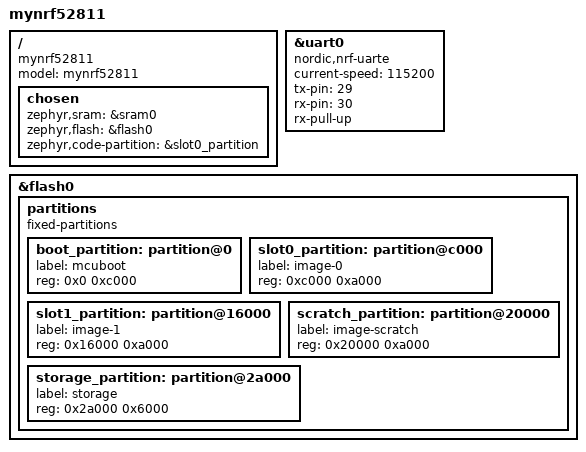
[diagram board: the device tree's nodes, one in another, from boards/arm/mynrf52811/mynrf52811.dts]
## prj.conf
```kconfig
# 配置文件

# 使能串口
CONFIG_SERIAL=y
CONFIG_NRFX_UARTE0=y
CONFIG_UART_ASYNC_API=y

# 使能以及配置蓝牙
CONFIG_BT=y
CONFIG_BT_DEVICE_NAME="ble_thomas"
CONFIG_BT_HCI_TX_STACK_SIZE=640
CONFIG_BT_PERIPHERAL=y
CONFIG_BT_PHY_UPDATE=n
CONFIG_BT_DATA_LEN_UPDATE=n
CONFIG_BT_BUF_EVT_RX_COUNT=2
CONFIG_BT_BUF_EVT_DISCARDABLE_COUNT=1
CONFIG_BT_ASSERT=n
CONFIG_BT_HCI_TX_STACK_SIZE_WITH_PROMPT=y
CONFIG_BT_MAX_PAIRED=1
CONFIG_BT_L2CAP_TX_BUF_COUNT=2
CONFIG_BT_GATT_SERVICE_CHANGED=n
CONFIG_BT_GAP_PERIPHERAL_PREF_PARAMS=n
CONFIG_BT_CTLR_PRIVACY=n
CONFIG_BT_MAX_CONN=1


# 内存优化，修改部分任务内存占用
CONFIG_DEBUG_THREAD_INFO=y
CONFIG_DEBUG_OPTIMIZATIONS=y
CONFIG_SYSTEM_WORKQUEUE_STACK_SIZE=1536
CONFIG_MAIN_STACK_SIZE=512
CONFIG_IDLE_STACK_SIZE=128
CONFIG_ISR_STACK_SIZE=1024
CONFIG_TIMESLICING=n

CONFIG_BT_EXT_ADV=y
CONFIG_BT_PER_ADV=y
CONFIG_BT_DF=y
CONFIG_BT_DF_CONNECTIONLESS_CTE_RX=y
CONFIG_BT_DF_CTE_RX_AOA=n
CONFIG_BT_OBSERVER=y
CONFIG_BT_PER_ADV_SYNC=y
```

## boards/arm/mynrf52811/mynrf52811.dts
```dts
// Copyright (c) 2022 Nordic Semiconductor ASA
// SPDX-License-Identifier: Apache-2.0

/dts-v1/;
#include <nordic/nrf52811_qfaa.dtsi>

/ {
	model = "mynrf52811";
	compatible = "mynrf52811";

	chosen {
		zephyr,sram = &sram0;
		zephyr,flash = &flash0;
		zephyr,code-partition = &slot0_partition;
	};
};

&uart0 {
	compatible = "nordic,nrf-uarte";
	status = "okay";
	current-speed = <115200>;
	tx-pin = <29>;
	rx-pin = <30>;
	rx-pull-up;
   //  rts-pin = <2>;
   //  cts-pin = <31>;
   //  cts-pull-up;
};


&flash0 {
	partitions {
		compatible = "fixed-partitions";
		#address-cells = <1>;
		#size-cells = <1>;

		boot_partition: partition@0 {
			label = "mcuboot";
			reg = <0x0 0xc000>;
		};
		slot0_partition: partition@c000 {
			label = "image-0";
			reg = <0xc000 0xa000>;
		};
		slot1_partition: partition@16000 {
			label = "image-1";
			reg = <0x16000 0xa000>;
		};
		scratch_partition: partition@20000 {
			label = "image-scratch";
			reg = <0x20000 0xa000>;
		};
		storage_partition: partition@2a000 {
			label = "storage";
			reg = <0x2a000 0x6000>;
		};
	};
};
```

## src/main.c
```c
/****
 * 
 * 
 * */
#include <zephyr.h>
#include "mybluetooth.h"
#include "myuart.h"
#include "uart_profile.h"


K_THREAD_DEFINE(ble_write_thread_id, BT_UART_STACKSIZE, ble_write_thread, NULL, NULL,
		NULL, BT_UART_PRIORITY, 0, 0);

void main(void)
{
	int err;
	
	NRFX_DELAY_US(1000000);
	uart_init();

	err = bt_enable(NULL);
	if (err){
		printk("ble init faild\r\n");
	}
	/* 发送初始化成功的消息 */
	k_sem_give(&ble_init_ok);
	printk("ble init success!\r\n");
	ble_had_been_inited = 1;

	/* 开始广播 */
	bt_advertising_start();
	while (1){
		printk("hello world\r\n");
		k_sleep(K_MSEC(2000));
	}
}
```

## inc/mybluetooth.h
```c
#ifndef __MYBLUETOOTH_H
#define __MYBLUETOOTH_H

#include <drivers/uart.h>
#include <bluetooth/bluetooth.h>
#include <bluetooth/hci.h>

#define DEVICE_NAME CONFIG_BT_DEVICE_NAME
#define DEVICE_NAME_LEN (sizeof(DEVICE_NAME) - 1)

extern uint8_t ble_had_been_inited;
extern struct bt_conn *current_conn;

void bt_scan_enable(void);
void bt_advertising_start(void);
void connected_cb(struct bt_conn *conn, uint8_t err);
void disconnected_cb(struct bt_conn *conn, uint8_t reason);
void scan_cb(const bt_addr_le_t *addr, int8_t rssi, uint8_t adv_type, struct net_buf_simple *buf);


#endif
```

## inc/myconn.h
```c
#ifndef __MYCONN_H
#define __MYCONN_H

#include <bluetooth/bluetooth.h>


void connected(struct bt_conn *conn, uint8_t err);
void disconnected(struct bt_conn *conn, uint8_t reason);

#endif
```

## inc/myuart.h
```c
#ifndef __MYUART_H
#define __MYUART_H

#include <drivers/uart.h>

#define UART_BUF_SIZE 40
#define UART_RX_TIMEOUT 50

/* 串口数据格式 */
struct uart_data_t {
	void *fifo_reserved;
	uint8_t  data[UART_BUF_SIZE];
	uint16_t len;
};

extern const struct device *uart;

int uart_init(void);
void ble_write_thread(void);

void uart_cb(const struct device *, struct uart_event *, void *);


#endif
```

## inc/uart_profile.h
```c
#ifndef __UART_PROFILE_H
#define __UART_PROFILE_H

#include <drivers/uart.h>
#include "bluetooth/uuid.h"
#include "bluetooth/gatt.h"


/* 串口透传服务UUID */
#define UART_TP_UUID_VAL BT_UUID_128_ENCODE(0x64f499cc,0x3411, 0x461d, 0x8055, 0x333d0bc7d33c)

/* 发送特征UUID */
#define UART_TX_UUID_VAL BT_UUID_128_ENCODE(0x64f499cd,0x3411, 0x461d, 0x8055, 0x333d0bc7d33c)

/* 接收特征UUID */
#define UART_RX_UUID_VAL BT_UUID_128_ENCODE(0x64f499ce,0x3411, 0x461d, 0x8055, 0x333d0bc7d33c)

#define BT_UUID_UART_TP        BT_UUID_DECLARE_128(UART_TP_UUID_VAL)
#define BT_UUID_UART_RX        BT_UUID_DECLARE_128(UART_TX_UUID_VAL)
#define BT_UUID_UART_TX        BT_UUID_DECLARE_128(UART_RX_UUID_VAL)


#define BT_UART_STACKSIZE 256
#define BT_UART_PRIORITY 7

extern struct k_sem ble_init_ok;

/* 串口透传状态 */
enum bt_uart_send_status {
	/* 发送通知使能 */
	BT_UART_SEND_STATUS_ENABLED,
	/* 发送通知停止使能 */
	BT_UART_SEND_STATUS_DISABLED,
};


void bt_uart_ccc_cfg_changed(const struct bt_gatt_attr *, uint16_t);
ssize_t ble_uart_receive_cb(struct bt_conn*, const struct bt_gatt_attr*, const void*, uint16_t, uint16_t, uint8_t);


#endif
```

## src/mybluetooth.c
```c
#include "mybluetooth.h"
#include "uart_profile.h"


/* 蓝牙初始化完成标志 */
uint8_t ble_had_been_inited = 0;

struct bt_conn *current_conn;

/* 连接相关回调函数注册 */
BT_CONN_CB_DEFINE(conn_callbacks) = {
	.connected    = connected_cb,
	.disconnected = disconnected_cb,
};


/* 广播发送的信息 */
static const struct bt_data ad[] = {
	BT_DATA_BYTES(BT_DATA_FLAGS, (BT_LE_AD_GENERAL | BT_LE_AD_NO_BREDR)),
	BT_DATA(BT_DATA_NAME_COMPLETE, DEVICE_NAME, DEVICE_NAME_LEN),
}; 

/* 对方扫描回应的信息 */
static const struct bt_data sd[] = {
	BT_DATA_BYTES(BT_DATA_UUID128_ALL, UART_TP_UUID_VAL),
};

/* 扫描参数 */
const struct bt_le_scan_param scan_param = {
		.type       = BT_HCI_LE_SCAN_PASSIVE,
		.options    = BT_LE_SCAN_OPT_NONE,
		.interval   = 0x00A0,
		.window     = 0x0050,
	};


/**
 * @brief 蓝牙开始广播 
 */
void bt_advertising_start(void){
	int err;
	/* Start advertising */
	err = bt_le_adv_start(BT_LE_ADV_CONN, ad, ARRAY_SIZE(ad),
			      sd, ARRAY_SIZE(sd));
    if (err) {
		printk("Advertising failed to start (err %d)\r\n", err);
		return;
	}
	printk("Advertising started!\r\n");
}


/**
 * @brief 初始化并开始扫描 
 */
void bt_scan_enable(void){
	int err;

	err = bt_le_scan_start(&scan_param, scan_cb);
	if (err) {
		printk("Starting scanning failed (err %d)\n", err);
		return;
	}
}

/**
 * @brief 扫描回调函数，每次扫描到东西都会进入到里面
 * 
 * @param addr 		：广播方地址
 * @param rssi 		：接收功率
 * @param adv_type 	：类型，被动扫描还是主动扫描（可以用来判断是广播数据还是扫描响应数据）
 * @param buf 		：接收的广播数据
 */
void scan_cb(const bt_addr_le_t *addr, int8_t rssi, uint8_t adv_type,
		    struct net_buf_simple *buf)
{
	static uint8_t name_buf[11] = {0};
	if (adv_type == BT_HCI_LE_SCAN_PASSIVE){
		if (buf->len > 10){
			if ((uint8_t)buf->data[3] == 11){
				memcpy(name_buf, &(buf->data[5]), 10);
				printk("name is: %s \r\n", name_buf);
				printk("rssi is: %d \r\n", rssi);
			}
		}
	}
}


/**
 * @brief 连接成功回调函数
 * 
 * @param conn 	:连接句柄
 * @param err 	:连接错误
 */
void connected_cb(struct bt_conn *conn, uint8_t err)
{

	if (err) {
		printk("Connection failed (err %u)", err);
		return;
	}

	printk("Connected!!\r\n");

	current_conn = bt_conn_ref(conn);
}


/**
 * @brief 断开连接回调函数
 * 
 * @param conn 		:连接句柄
 * @param reason 	:断开原因
 */
void disconnected_cb(struct bt_conn *conn, uint8_t reason)
{

	printk("Disconnected (reason %u)\r\n", reason);

	if (current_conn) {
		bt_conn_unref(current_conn);
		current_conn = NULL;
	}
}
```

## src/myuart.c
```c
#include "myuart.h"

/* 串口设备 */
const struct device *uart;


/**
 * @breif: 串口初始化
 */
int uart_init(void){
	int err;
	static struct uart_data_t rx;

	/* 初始化串口设备 */
	uart = device_get_binding(DT_LABEL(DT_NODELABEL(uart0)));
	if (!uart) {
		return -ENXIO;
	}

	/* 设置串口回调函数 */
	err = uart_callback_set(uart, uart_cb, NULL);
	if (err) {
		return err;
	}

	/* 初始化串口接收 */
	return uart_rx_enable(uart, rx.data, sizeof(rx.data),
			      UART_RX_TIMEOUT);
}


/**
 * @breif: 重定向printk函数，让printk打印向串口
 */
int arch_printk_char_out(int c)
{

	uart_poll_out(uart, (unsigned char)c);
	/* do nothing */
	return c;
}


/**
 * @breif: 串口回调函数，目前没用
 * @param
 */
__weak void uart_cb(const struct device *dev, struct uart_event *evt, void *user_data){

}
```

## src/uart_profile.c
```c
#include "uart_profile.h"
#include "myuart.h"
#include "mybluetooth.h"


K_FIFO_DEFINE(fifo_uart_rx_data);
K_SEM_DEFINE(ble_init_ok, 0, 1);

/* UART Service Declaration */
BT_GATT_SERVICE_DEFINE(us_svc,
BT_GATT_PRIMARY_SERVICE(BT_UUID_UART_TP),
	BT_GATT_CHARACTERISTIC(BT_UUID_UART_TX,
			       BT_GATT_CHRC_NOTIFY,
			       BT_GATT_PERM_READ,
			       NULL, NULL, NULL),
    BT_GATT_CCC(bt_uart_ccc_cfg_changed, BT_GATT_PERM_READ | BT_GATT_PERM_WRITE),   /* 只要发送有通知都需要配合这个使用 */
	BT_GATT_CHARACTERISTIC(BT_UUID_UART_RX,
			       BT_GATT_CHRC_WRITE |
			       BT_GATT_CHRC_WRITE_WITHOUT_RESP,
			       BT_GATT_PERM_READ | BT_GATT_PERM_WRITE,
			       NULL, ble_uart_receive_cb, NULL),
);



ssize_t ble_uart_receive_cb(struct bt_conn *conn,
			  const struct bt_gatt_attr *attr,
			  const void *buf,
			  uint16_t len,
			  uint16_t offset,
			  uint8_t flags){

    if (ble_had_been_inited == 1){
        uart_tx(uart, buf, len, SYS_FOREVER_MS);
    }
    return len;
}


void bt_uart_ccc_cfg_changed(const struct bt_gatt_attr *attr,
				  uint16_t value){
    printk("notification has been changed\r\n");

}


int bt_uart_send(struct bt_conn *conn, const uint8_t *data, uint16_t len)
{
	struct bt_gatt_notify_params params = {0};
	const struct bt_gatt_attr *attr = &us_svc.attrs[2];

	params.attr = attr;
	params.data = data;
	params.len = len;
	params.func = NULL;

	if (!conn) {
		//printk("Notification send to all connected peers\r\n");
		return bt_gatt_notify_cb(NULL, &params);
	} else if (bt_gatt_is_subscribed(conn, attr, BT_GATT_CCC_NOTIFY)) {
		return bt_gatt_notify_cb(conn, &params);
	} else {
		return -EINVAL;
	}
}


void ble_write_thread(void)
{
	/* Don't go any further until BLE is initialized */
	k_sem_take(&ble_init_ok, K_FOREVER);
    //printk("write thread started!\r\n");
	for (;;) {
		/* Wait indefinitely for data to be sent over bluetooth */
		struct uart_data_t *buf = k_fifo_get(&fifo_uart_rx_data,
						     K_FOREVER);
        //printk("data len: %d \r\n", buf->len);

		if (bt_uart_send(current_conn, buf->data, buf->len)) {
			//printk("Failed to send data over BLE connection\r\n");
		}

		k_free(buf);
	}
}





/**
 * @breif: 串口回调函数，目前没用
 * @param
 */
void uart_cb(const struct device *dev, struct uart_event *evt, void *user_data){
	static bool buf_release;
	struct uart_data_t *buf;

	switch (evt->type) {
	case UART_RX_RDY:
		buf = CONTAINER_OF(evt->data.rx.buf, struct uart_data_t, data);
		buf->len = (uint16_t)evt->data.rx.len;
		buf_release = false;
//        printk("buf_len:%d\r\n", buf->len);

        k_fifo_put(&fifo_uart_rx_data, buf);
        buf_release = true;
//        uart_rx_disable(uart);
		// if (buf->len == UART_BUF_SIZE) {
		// 	k_fifo_put(&fifo_uart_rx_data, buf);
		// } else if ((evt->data.rx.buf[buf->len - 1] == '\n') ||
		// 	  (evt->data.rx.buf[buf->len - 1] == '\r')) {
		// 	k_fifo_put(&fifo_uart_rx_data, buf);
		// 	current_buf = evt->data.rx.buf;
		// 	buf_release = true;
		// 	uart_rx_disable(uart);
		// }
		break;
	default:
		break;
	}
}
```
